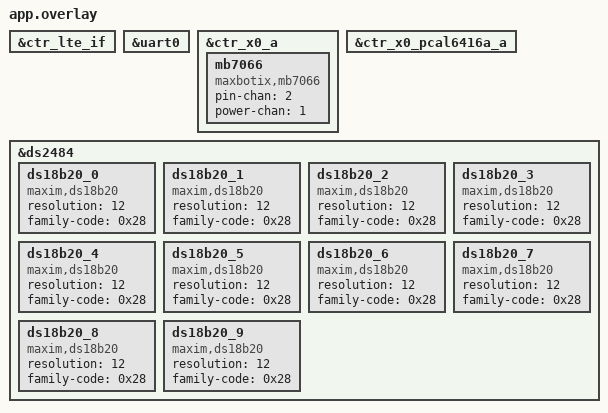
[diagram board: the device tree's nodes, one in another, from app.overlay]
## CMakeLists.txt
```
#
# Copyright (c) 2024 HARDWARIO a.s.
#
#  SPDX-License-Identifier: LicenseRef-HARDWARIO-5-Clause
#

cmake_minimum_required(VERSION 3.20.0)

set(ENV{FW_BUNDLE} "com.hardwario.chester.range")
set(ENV{FW_VERSION} "v1.0.0")
set(ENV{FW_NAME} "CHESTER Range")

find_package(Zephyr REQUIRED HINTS $ENV{ZEPHYR_BASE})

project(chester-range)

target_sources(app PRIVATE src/app_sensor.c)
target_sources(app PRIVATE src/main.c)
target_sources(app PRIVATE src/app_shell.c)
target_sources(app PRIVATE src/app_init.c)
target_sources(app PRIVATE src/app_data.c)
target_sources(app PRIVATE src/app_power.c)
target_sources(app PRIVATE src/app_send.c)
target_sources(app PRIVATE src/app_config.c)
target_sources(app PRIVATE src/app_work.c)
target_sources(app PRIVATE src/app_handler.c)
target_sources(app PRIVATE src/app_backup.c)
target_sources(app PRIVATE src/app_cbor.c)
```

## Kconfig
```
#
# Copyright (c) 2024 HARDWARIO a.s.
#
# SPDX-License-Identifier: LicenseRef-HARDWARIO-5-Clause
#

menu "Application"

# CHESTER RANGE Project | RANGE Variant 

# LTE 
config SHIELD_CTR_LTE
	bool "Enable SHIELD_CTR_LTE"
	default y 

config CTR_LTE
	default y
# MB7066_A 
config SHIELD_CTR_A
	bool "Enable SHIELD_CTR_MB7066_A"
	default y 

config CTR_X0
	default y

config MB7066
	default y
# DS18B20 
config SHIELD_CTR_DS18B20
	bool "Enable SHIELD_CTR_DS18B20"
	default y 

config CTR_DS18B20
	default y
# REPORT_JITTER 
config APP_REPORT_JITTER
	bool "Add random time jitter to report transfers"
	default y 
	select ENTROPY_GENERATOR

endmenu

menu "Zephyr Kernel"
source "Kconfig.zephyr"
endmenu
```

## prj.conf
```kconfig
#
# Copyright (c) 2024 HARDWARIO a.s.
#
#  SPDX-License-Identifier: LicenseRef-HARDWARIO-5-Clause
#

# Configurations
CONFIG_ADC_SHELL=y
CONFIG_CTR_ACCEL=y
CONFIG_CTR_BATT=y
CONFIG_CTR_BUTTON=y
CONFIG_CTR_BUF=y
CONFIG_CTR_DEFAULTS=y
CONFIG_CTR_INFO=y
CONFIG_CTR_LED=y
CONFIG_CTR_LOG=y
CONFIG_CTR_RTC=y
CONFIG_CTR_THERM=y
CONFIG_CTR_WDOG=y
CONFIG_TINYCRYPT=y
CONFIG_TINYCRYPT_SHA256=y
CONFIG_ZCBOR=y
CONFIG_ZCBOR_STOP_ON_ERROR=y
CONFIG_CTR_LTE_CLKSYNC=y
CONFIG_MB7066_TIMER4=y
CONFIG_MB7066_SAMPLE_COUNT=1

# Extra configurations
CONFIG_ADC_TLA2021_INIT_PRIORITY=60

# USER CODE BEGIN Config 
# USER CODE END Config
```

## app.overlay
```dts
/*
 * Copyright (c) 2024 HARDWARIO a.s.
 *
 * SPDX-License-Identifier: LicenseRef-HARDWARIO-5-Clause
 */

/* CHESTER RANGE Project | RANGE Variant */

/* LTE  */
&ctr_lte_if {
	status = "okay";
};

&uart0 {
	status = "okay";
};
/* MB7066_A  */
&ctr_x0_a {
	status = "okay";
	mb7066: mb7066 {
		compatible = "maxbotix,mb7066";
		status = "okay";
		pin-chan = <2>;
		power-chan = <1>;
	};
};

&ctr_x0_pcal6416a_a {
	status = "okay";
};
/* DS18B20  */
&ds2484 {
	ds18b20_0: ds18b20_0 {
		compatible = "maxim,ds18b20";
		resolution = <12>;
		family-code = <0x28>;
	};

	ds18b20_1: ds18b20_1 {
		compatible = "maxim,ds18b20";
		resolution = <12>;
		family-code = <0x28>;
	};

	ds18b20_2: ds18b20_2 {
		compatible = "maxim,ds18b20";
		resolution = <12>;
		family-code = <0x28>;
	};

	ds18b20_3: ds18b20_3 {
		compatible = "maxim,ds18b20";
		resolution = <12>;
		family-code = <0x28>;
	};

	ds18b20_4: ds18b20_4 {
		compatible = "maxim,ds18b20";
		resolution = <12>;
		family-code = <0x28>;
	};

	ds18b20_5: ds18b20_5 {
		compatible = "maxim,ds18b20";
		resolution = <12>;
		family-code = <0x28>;
	};

	ds18b20_6: ds18b20_6 {
		compatible = "maxim,ds18b20";
		resolution = <12>;
		family-code = <0x28>;
	};

	ds18b20_7: ds18b20_7 {
		compatible = "maxim,ds18b20";
		resolution = <12>;
		family-code = <0x28>;
	};

	ds18b20_8: ds18b20_8 {
		compatible = "maxim,ds18b20";
		resolution = <12>;
		family-code = <0x28>;
	};

	ds18b20_9: ds18b20_9 {
		compatible = "maxim,ds18b20";
		resolution = <12>;
		family-code = <0x28>;
	};
};
```

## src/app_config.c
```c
/*
 * Copyright (c) 2024 HARDWARIO a.s.
 *
 * SPDX-License-Identifier: LicenseRef-HARDWARIO-5-Clause
 */

#include "app_config.h"

/* CHESTER includes */
#include <chester/ctr_config.h>

/* Zephyr includes */
#include <zephyr/init.h>
#include <zephyr/kernel.h>
#include <zephyr/logging/log.h>
#include <zephyr/settings/settings.h>
#include <zephyr/shell/shell.h>

/* Standard includes */
#include <ctype.h>
#include <stdbool.h>
#include <stdio.h>
#include <stdlib.h>
#include <string.h>

/* USER CODE BEGIN Includes */
/* USER CODE END Includes */

LOG_MODULE_REGISTER(app_config, LOG_LEVEL_DBG);

#define SETTINGS_PFX "chester-range"

struct app_config g_app_config;

static struct app_config m_app_config_interim = {
	.interval_report = 1800,
	.interval_aggreg = 300,
	.interval_sample = 60,
	.event_report_delay = 1,
	.event_report_rate = 30,
	.backup_report_connected = true,
	.backup_report_disconnected = true,

	/* USER CODE BEGIN Struct Variables */
	/* USER CODE END Struct Variables */
};

/* USER CODE BEGIN Variables */
/* USER CODE END Variables */

static void print_interval_report(const struct shell *shell)
{
	shell_print(shell, "app config interval-report  %d",
			m_app_config_interim.interval_report);
}

int app_config_cmd_config_interval_report(const struct shell *shell, size_t argc, char **argv)
{
	if (argc == 1) {
		print_interval_report(shell);
		return 0;
	}
	if (argc == 2) {
		size_t len = strlen(argv[1]);
		for (size_t i = 0; i < len; i++) {
			if (!isdigit((int)argv[1][i])) {
				shell_error(shell, "invalid format");
				return -EINVAL;
			}
		}
		long value = strtol(argv[1], NULL, 10);
		if (value < 30 || value > 86400) {
			shell_error(shell, "invalid range");
			return -EINVAL;
		}
		m_app_config_interim.interval_report = (int)value;
		return 0;
	}
	shell_help(shell);
	return -EINVAL;
}

static void print_interval_aggreg(const struct shell *shell)
{
	shell_print(shell, "app config interval-aggreg  %d",
			m_app_config_interim.interval_aggreg);
}

int app_config_cmd_config_interval_aggreg(const struct shell *shell, size_t argc, char **argv)
{
	if (argc == 1) {
		print_interval_aggreg(shell);
		return 0;
	}
	if (argc == 2) {
		size_t len = strlen(argv[1]);
		for (size_t i = 0; i < len; i++) {
			if (!isdigit((int)argv[1][i])) {
				shell_error(shell, "invalid format");
				return -EINVAL;
			}
		}
		long value = strtol(argv[1], NULL, 10);
		if (value < 1 || value > 86400) {
			shell_error(shell, "invalid range");
			return -EINVAL;
		}
		m_app_config_interim.interval_aggreg = (int)value;
		return 0;
	}
	shell_help(shell);
	return -EINVAL;
}

static void print_interval_sample(const struct shell *shell)
{
	shell_print(shell, "app config interval-sample  %d",
			m_app_config_interim.interval_sample);
}

int app_config_cmd_config_interval_sample(const struct shell *shell, size_t argc, char **argv)
{
	if (argc == 1) {
		print_interval_sample(shell);
		return 0;
	}
	if (argc == 2) {
		size_t len = strlen(argv[1]);
		for (size_t i = 0; i < len; i++) {
			if (!isdigit((int)argv[1][i])) {
				shell_error(shell, "invalid format");
				return -EINVAL;
			}
		}
		long value = strtol(argv[1], NULL, 10);
		if (value < 1 || value > 86400) {
			shell_error(shell, "invalid range");
			return -EINVAL;
		}
		m_app_config_interim.interval_sample = (int)value;
		return 0;
	}
	shell_help(shell);
	return -EINVAL;
}

static void print_event_report_delay(const struct shell *shell)
{
	shell_print(shell, "app config event-report-delay  %d",
			m_app_config_interim.event_report_delay);
}

int app_config_cmd_config_event_report_delay(const struct shell *shell, size_t argc, char **argv)
{
	if (argc == 1) {
		print_event_report_delay(shell);
		return 0;
	}
	if (argc == 2) {
		size_t len = strlen(argv[1]);
		for (size_t i = 0; i < len; i++) {
			if (!isdigit((int)argv[1][i])) {
				shell_error(shell, "invalid format");
				return -EINVAL;
			}
		}
		long value = strtol(argv[1], NULL, 10);
		if (value < 1 || value > 86400) {
			shell_error(shell, "invalid range");
			return -EINVAL;
		}
		m_app_config_interim.event_report_delay = (int)value;
		return 0;
	}
	shell_help(shell);
	return -EINVAL;
}

static void print_event_report_rate(const struct shell *shell)
{
	shell_print(shell, "app config event-report-rate  %d",
			m_app_config_interim.event_report_rate);
}

int app_config_cmd_config_event_report_rate(const struct shell *shell, size_t argc, char **argv)
{
	if (argc == 1) {
		print_event_report_rate(shell);
		return 0;
	}
	if (argc == 2) {
		size_t len = strlen(argv[1]);
		for (size_t i = 0; i < len; i++) {
			if (!isdigit((int)argv[1][i])) {
				shell_error(shell, "invalid format");
				return -EINVAL;
			}
		}
		long value = strtol(argv[1], NULL, 10);
		if (value < 1 || value > 3600) {
			shell_error(shell, "invalid range");
			return -EINVAL;
		}
		m_app_config_interim.event_report_rate = (int)value;
		return 0;
	}
	shell_help(shell);
	return -EINVAL;
}

static void print_backup_report_connected(const struct shell *shell)
{
	shell_print(shell, "app config backup-report-connected  %s",
			m_app_config_interim.backup_report_connected ? "true" : "false");
}

int app_config_cmd_config_backup_report_connected(const struct shell *shell, size_t argc, char **argv)
{
	if (argc == 1) {
		print_backup_report_connected(shell);                                                    
		return 0;
	}
	if (argc == 2) {
		bool is_false = !strcmp(argv[1], "false");
		bool is_true = !strcmp(argv[1], "true");
		if (is_false) {
			m_app_config_interim.backup_report_connected = false;
		} else if (is_true) {
			m_app_config_interim.backup_report_connected = true;
		} else {
			shell_error(shell, "invalid format");
			return -EINVAL;
		}
		return 0;
	}
	shell_help(shell);
	return -EINVAL;
}

static void print_backup_report_disconnected(const struct shell *shell)
{
	shell_print(shell, "app config backup-report-disconnected  %s",
			m_app_config_interim.backup_report_disconnected ? "true" : "false");
}

int app_config_cmd_config_backup_report_disconnected(const struct shell *shell, size_t argc, char **argv)
{
	if (argc == 1) {
		print_backup_report_disconnected(shell);                                                    
		return 0;
	}
	if (argc == 2) {
		bool is_false = !strcmp(argv[1], "false");
		bool is_true = !strcmp(argv[1], "true");
		if (is_false) {
			m_app_config_interim.backup_report_disconnected = false;
		} else if (is_true) {
			m_app_config_interim.backup_report_disconnected = true;
		} else {
			shell_error(shell, "invalid format");
			return -EINVAL;
		}
		return 0;
	}
	shell_help(shell);
	return -EINVAL;
}

static void print_hygro_t_alarm_hi_report(const struct shell *shell)
{
	shell_print(shell, "app config hygro-t-alarm-hi-report  %s",
			m_app_config_interim.hygro_t_alarm_hi_report ? "true" : "false");
}

int app_config_cmd_config_hygro_t_alarm_hi_report(const struct shell *shell, size_t argc, char **argv)
{
	if (argc == 1) {
		print_hygro_t_alarm_hi_report(shell);                                                    
		return 0;
	}
	if (argc == 2) {
		bool is_false = !strcmp(argv[1], "false");
		bool is_true = !strcmp(argv[1], "true");
		if (is_false) {
			m_app_config_interim.hygro_t_alarm_hi_report = false;
		} else if (is_true) {
			m_app_config_interim.hygro_t_alarm_hi_report = true;
		} else {
			shell_error(shell, "invalid format");
			return -EINVAL;
		}
		return 0;
	}
	shell_help(shell);
	return -EINVAL;
}

static void print_hygro_t_alarm_lo_report(const struct shell *shell)
{
	shell_print(shell, "app config hygro-t-alarm-lo-report  %s",
			m_app_config_interim.hygro_t_alarm_lo_report ? "true" : "false");
}

int app_config_cmd_config_hygro_t_alarm_lo_report(const struct shell *shell, size_t argc, char **argv)
{
	if (argc == 1) {
		print_hygro_t_alarm_lo_report(shell);                                                    
		return 0;
	}
	if (argc == 2) {
		bool is_false = !strcmp(argv[1], "false");
		bool is_true = !strcmp(argv[1], "true");
		if (is_false) {
			m_app_config_interim.hygro_t_alarm_lo_report = false;
		} else if (is_true) {
			m_app_config_interim.hygro_t_alarm_lo_report = true;
		} else {
			shell_error(shell, "invalid format");
			return -EINVAL;
		}
		return 0;
	}
	shell_help(shell);
	return -EINVAL;
}

static void print_hygro_t_alarm_hi_thr(const struct shell *shell)
{
	shell_print(shell, "app config hygro-t-alarm-hi-thr %.1f",
			m_app_config_interim.hygro_t_alarm_hi_thr);
}

int app_config_cmd_config_hygro_t_alarm_hi_thr(const struct shell *shell, size_t argc, char **argv)
{
	if (argc == 1) {
		print_hygro_t_alarm_hi_thr(shell);
		return 0;
	}
	if (argc == 2) {
		float value;
		int ret = sscanf(argv[1], "%f", &value);
		if (ret != 1) {
			shell_error(shell, "invalid value");
			return -EINVAL;
		}
		if (value < -40.0 || value > 125.0) 
		{
			shell_error(shell, "invalid range");
			return -EINVAL;
		}
		m_app_config_interim.hygro_t_alarm_hi_thr = value;
		return 0;
	}
	shell_help(shell);
	return -EINVAL;
}

static void print_hygro_t_alarm_hi_hst(const struct shell *shell)
{
	shell_print(shell, "app config hygro-t-alarm-hi-hst %.1f",
			m_app_config_interim.hygro_t_alarm_hi_hst);
}

int app_config_cmd_config_hygro_t_alarm_hi_hst(const struct shell *shell, size_t argc, char **argv)
{
	if (argc == 1) {
		print_hygro_t_alarm_hi_hst(shell);
		return 0;
	}
	if (argc == 2) {
		float value;
		int ret = sscanf(argv[1], "%f", &value);
		if (ret != 1) {
			shell_error(shell, "invalid value");
			return -EINVAL;
		}
		if (value < 0.0 || value > 100.0) 
		{
			shell_error(shell, "invalid range");
			return -EINVAL;
		}
		m_app_config_interim.hygro_t_alarm_hi_hst = value;
		return 0;
	}
	shell_help(shell);
	return -EINVAL;
}

static void print_hygro_t_alarm_lo_thr(const struct shell *shell)
{
	shell_print(shell, "app config hygro-t-alarm-lo-thr %.1f",
			m_app_config_interim.hygro_t_alarm_lo_thr);
}

int app_config_cmd_config_hygro_t_alarm_lo_thr(const struct shell *shell, size_t argc, char **argv)
{
	if (argc == 1) {
		print_hygro_t_alarm_lo_thr(shell);
		return 0;
	}
	if (argc == 2) {
		float value;
		int ret = sscanf(argv[1], "%f", &value);
		if (ret != 1) {
			shell_error(shell, "invalid value");
			return -EINVAL;
		}
		if (value < -40.0 || value > 125.0) 
		{
			shell_error(shell, "invalid range");
			return -EINVAL;
		}
		m_app_config_interim.hygro_t_alarm_lo_thr = value;
		return 0;
	}
	shell_help(shell);
	return -EINVAL;
}

static void print_hygro_t_alarm_lo_hst(const struct shell *shell)
{
	shell_print(shell, "app config hygro-t-alarm-lo-hst %.1f",
			m_app_config_interim.hygro_t_alarm_lo_hst);
}

int app_config_cmd_config_hygro_t_alarm_lo_hst(const struct shell *shell, size_t argc, char **argv)
{
	if (argc == 1) {
		print_hygro_t_alarm_lo_hst(shell);
		return 0;
	}
	if (argc == 2) {
		float value;
		int ret = sscanf(argv[1], "%f", &value);
		if (ret != 1) {
			shell_error(shell, "invalid value");
			return -EINVAL;
		}
		if (value < 0.0 || value > 100.0) 
		{
			shell_error(shell, "invalid range");
			return -EINVAL;
		}
		m_app_config_interim.hygro_t_alarm_lo_hst = value;
		return 0;
	}
	shell_help(shell);
	return -EINVAL;
}

int app_config_cmd_config_show(const struct shell *shell, size_t argc, char **argv)
{
	print_interval_report(shell);
	print_interval_aggreg(shell);
	print_interval_sample(shell);
	print_event_report_delay(shell);
	print_event_report_rate(shell);
	print_backup_report_connected(shell);
	print_backup_report_disconnected(shell);
	print_hygro_t_alarm_hi_report(shell);
	print_hygro_t_alarm_lo_report(shell);
	print_hygro_t_alarm_hi_thr(shell);
	print_hygro_t_alarm_hi_hst(shell);
	print_hygro_t_alarm_lo_thr(shell);
	print_hygro_t_alarm_lo_hst(shell);
	
	return 0;
}

/* USER CODE BEGIN Functions 1 */
/* USER CODE END Functions 1 */

static int h_commit(void)
{
	LOG_DBG("Loaded settings in full");
	memcpy(&g_app_config, &m_app_config_interim, sizeof(g_app_config));

	return 0;
}

static int h_set(const char *key, size_t len, settings_read_cb read_cb, void *cb_arg) 
{
	int ret;
	const char *next;
	if (settings_name_steq(key, "interval-report", &next) && !next) {
		if (len != sizeof(m_app_config_interim.interval_report)) {
			return -EINVAL;
		}
		ret = read_cb(cb_arg, &m_app_config_interim.interval_report, len);
		if (ret < 0) {
			LOG_ERR("Call `read_cb` failed: %d", ret);
			return ret;
		}
		return 0;
	}

	if (settings_name_steq(key, "interval-aggreg", &next) && !next) {
		if (len != sizeof(m_app_config_interim.interval_aggreg)) {
			return -EINVAL;
		}
		ret = read_cb(cb_arg, &m_app_config_interim.interval_aggreg, len);
		if (ret < 0) {
			LOG_ERR("Call `read_cb` failed: %d", ret);
			return ret;
		}
		return 0;
	}

	if (settings_name_steq(key, "interval-sample", &next) && !next) {
		if (len != sizeof(m_app_config_interim.interval_sample)) {
			return -EINVAL;
		}
		ret = read_cb(cb_arg, &m_app_config_interim.interval_sample, len);
		if (ret < 0) {
			LOG_ERR("Call `read_cb` failed: %d", ret);
			return ret;
		}
		return 0;
	}

	if (settings_name_steq(key, "event-report-delay", &next) && !next) {
		if (len != sizeof(m_app_config_interim.event_report_delay)) {
			return -EINVAL;
		}
		ret = read_cb(cb_arg, &m_app_config_interim.event_report_delay, len);
		if (ret < 0) {
			LOG_ERR("Call `read_cb` failed: %d", ret);
			return ret;
		}
		return 0;
	}

	if (settings_name_steq(key, "event-report-rate", &next) && !next) {
		if (len != sizeof(m_app_config_interim.event_report_rate)) {
			return -EINVAL;
		}
		ret = read_cb(cb_arg, &m_app_config_interim.event_report_rate, len);
		if (ret < 0) {
			LOG_ERR("Call `read_cb` failed: %d", ret);
			return ret;
		}
		return 0;
	}

	if (settings_name_steq(key, "backup-report-connected", &next) && !next) {
		if (len != sizeof(m_app_config_interim.backup_report_connected)) {
			return -EINVAL;
		}
		ret = read_cb(cb_arg, &m_app_config_interim.backup_report_connected, len);
		if (ret < 0) {
			LOG_ERR("Call `read_cb` failed: %d", ret);
			return ret;
		}
		return 0;
	}

	if (settings_name_steq(key, "backup-report-disconnected", &next) && !next) {
		if (len != sizeof(m_app_config_interim.backup_report_disconnected)) {
			return -EINVAL;
		}
		ret = read_cb(cb_arg, &m_app_config_interim.backup_report_disconnected, len);
		if (ret < 0) {
			LOG_ERR("Call `read_cb` failed: %d", ret);
			return ret;
		}
		return 0;
	}

	if (settings_name_steq(key, "hygro-t-alarm-hi-report", &next) && !next) {
		if (len != sizeof(m_app_config_interim.hygro_t_alarm_hi_report)) {
			return -EINVAL;
		}
		ret = read_cb(cb_arg, &m_app_config_interim.hygro_t_alarm_hi_report, len);
		if (ret < 0) {
			LOG_ERR("Call `read_cb` failed: %d", ret);
			return ret;
		}
		return 0;
	}

	if (settings_name_steq(key, "hygro-t-alarm-lo-report", &next) && !next) {
		if (len != sizeof(m_app_config_interim.hygro_t_alarm_lo_report)) {
			return -EINVAL;
		}
		ret = read_cb(cb_arg, &m_app_config_interim.hygro_t_alarm_lo_report, len);
		if (ret < 0) {
			LOG_ERR("Call `read_cb` failed: %d", ret);
			return ret;
		}
		return 0;
	}

	if (settings_name_steq(key, "hygro-t-alarm-hi-thr", &next) && !next) {
		if (len != sizeof(m_app_config_interim.hygro_t_alarm_hi_thr)) {
			return -EINVAL;
		}
		ret = read_cb(cb_arg, &m_app_config_interim.hygro_t_alarm_hi_thr, len);
		if (ret < 0) {
			LOG_ERR("Call `read_cb` failed: %d", ret);
			return ret;
		}
		return 0;
	}

	if (settings_name_steq(key, "hygro-t-alarm-hi-hst", &next) && !next) {
		if (len != sizeof(m_app_config_interim.hygro_t_alarm_hi_hst)) {
			return -EINVAL;
		}
		ret = read_cb(cb_arg, &m_app_config_interim.hygro_t_alarm_hi_hst, len);
		if (ret < 0) {
			LOG_ERR("Call `read_cb` failed: %d", ret);
			return ret;
		}
		return 0;
	}

	if (settings_name_steq(key, "hygro-t-alarm-lo-thr", &next) && !next) {
		if (len != sizeof(m_app_config_interim.hygro_t_alarm_lo_thr)) {
			return -EINVAL;
		}
		ret = read_cb(cb_arg, &m_app_config_interim.hygro_t_alarm_lo_thr, len);
		if (ret < 0) {
			LOG_ERR("Call `read_cb` failed: %d", ret);
			return ret;
		}
		return 0;
	}

	if (settings_name_steq(key, "hygro-t-alarm-lo-hst", &next) && !next) {
		if (len != sizeof(m_app_config_interim.hygro_t_alarm_lo_hst)) {
			return -EINVAL;
		}
		ret = read_cb(cb_arg, &m_app_config_interim.hygro_t_alarm_lo_hst, len);
		if (ret < 0) {
			LOG_ERR("Call `read_cb` failed: %d", ret);
			return ret;
		}
		return 0;
	}

	/* USER CODE BEGIN Functions 2 */
	/* USER CODE END Functions 2 */

	return 0;
}

static int h_export(int (*export_func)(const char *name, const void *val, size_t val_len))
{
	int ret;

	ret = export_func("chester-range/interval-report", &m_app_config_interim.interval_report,
					  sizeof( m_app_config_interim.interval_report));
	if (ret < 0) {
		return ret;
	}

	ret = export_func("chester-range/interval-aggreg", &m_app_config_interim.interval_aggreg,
					  sizeof( m_app_config_interim.interval_aggreg));
	if (ret < 0) {
		return ret;
	}

	ret = export_func("chester-range/interval-sample", &m_app_config_interim.interval_sample,
					  sizeof( m_app_config_interim.interval_sample));
	if (ret < 0) {
		return ret;
	}

	ret = export_func("chester-range/event-report-delay", &m_app_config_interim.event_report_delay,
					  sizeof( m_app_config_interim.event_report_delay));
	if (ret < 0) {
		return ret;
	}

	ret = export_func("chester-range/event-report-rate", &m_app_config_interim.event_report_rate,
					  sizeof( m_app_config_interim.event_report_rate));
	if (ret < 0) {
		return ret;
	}

	ret = export_func("chester-range/backup-report-connected", &m_app_config_interim.backup_report_connected,
					  sizeof( m_app_config_interim.backup_report_connected));
	if (ret < 0) {
		return ret;
	}

	ret = export_func("chester-range/backup-report-disconnected", &m_app_config_interim.backup_report_disconnected,
					  sizeof( m_app_config_interim.backup_report_disconnected));
	if (ret < 0) {
		return ret;
	}

	ret = export_func("chester-range/hygro-t-alarm-hi-report", &m_app_config_interim.hygro_t_alarm_hi_report,
					  sizeof( m_app_config_interim.hygro_t_alarm_hi_report));
	if (ret < 0) {
		return ret;
	}

	ret = export_func("chester-range/hygro-t-alarm-lo-report", &m_app_config_interim.hygro_t_alarm_lo_report,
					  sizeof( m_app_config_interim.hygro_t_alarm_lo_report));
	if (ret < 0) {
		return ret;
	}

	ret = export_func("chester-range/hygro-t-alarm-hi-thr", &m_app_config_interim.hygro_t_alarm_hi_thr,
					  sizeof( m_app_config_interim.hygro_t_alarm_hi_thr));
	if (ret < 0) {
		return ret;
	}

	ret = export_func("chester-range/hygro-t-alarm-hi-hst", &m_app_config_interim.hygro_t_alarm_hi_hst,
					  sizeof( m_app_config_interim.hygro_t_alarm_hi_hst));
	if (ret < 0) {
		return ret;
	}

	ret = export_func("chester-range/hygro-t-alarm-lo-thr", &m_app_config_interim.hygro_t_alarm_lo_thr,
					  sizeof( m_app_config_interim.hygro_t_alarm_lo_thr));
	if (ret < 0) {
		return ret;
	}

	ret = export_func("chester-range/hygro-t-alarm-lo-hst", &m_app_config_interim.hygro_t_alarm_lo_hst,
					  sizeof( m_app_config_interim.hygro_t_alarm_lo_hst));
	if (ret < 0) {
		return ret;
	}

	/* USER CODE BEGIN Functions 3 */
	/* USER CODE END Functions 3 */

	return 0;
}

static int init(void) 
{
	int ret;

	LOG_INF("System initialization");

	static struct settings_handler sh = {
		.name = SETTINGS_PFX,
		.h_set = h_set,
		.h_commit = h_commit,
		.h_export = h_export,
	};

	ret = settings_register(&sh);

	if (ret < 0) {
		LOG_ERR("Call `settings_register` failed: %d", ret);
		return ret;
	}

	ret = settings_load_subtree(SETTINGS_PFX);

	if (ret < 0) {
		LOG_ERR("Call `settings_load_subtree` failed: %d", ret);
		return ret;
	}

	ctr_config_append_show(SETTINGS_PFX, app_config_cmd_config_show);

	/* USER CODE BEGIN Functions 4 */
	/* USER CODE END Functions 4 */

	return 0;
}

SYS_INIT(init, APPLICATION, CONFIG_APPLICATION_INIT_PRIORITY);
```

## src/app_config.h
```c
/*
 * Copyright (c) 2024 HARDWARIO a.s.
 *
 * SPDX-License-Identifier: LicenseRef-HARDWARIO-5-Clause
 */

#ifndef APP_CONFIG_H_
#define APP_CONFIG_H_

/* Zephyr includes */
#include <zephyr/shell/shell.h>

/* Standard includes */
#include <stdbool.h>
#include <stddef.h>

/* USER CODE BEGIN Includes */
/* USER CODE END Includes */

#ifdef __cplusplus
extern "C" {
#endif

struct app_config {
	int interval_report;
	int interval_aggreg;
	int interval_sample;
	int event_report_delay;
	int event_report_rate;
	bool backup_report_connected;
	bool backup_report_disconnected;
	bool hygro_t_alarm_hi_report;
	bool hygro_t_alarm_lo_report;
	float hygro_t_alarm_hi_thr;
	float hygro_t_alarm_hi_hst;
	float hygro_t_alarm_lo_thr;
	float hygro_t_alarm_lo_hst;

	/* USER CODE BEGIN Struct Variables */
	/* USER CODE END Struct Variables */
};

extern struct app_config g_app_config;

/* USER CODE BEGIN Variables */
/* USER CODE END Variables */

int app_config_cmd_config_show(const struct shell *shell, size_t argc, char **argv);
int app_config_cmd_config_interval_report(const struct shell *shell, size_t argc, char **argv);
int app_config_cmd_config_interval_aggreg(const struct shell *shell, size_t argc, char **argv);
int app_config_cmd_config_interval_sample(const struct shell *shell, size_t argc, char **argv);
int app_config_cmd_config_event_report_delay(const struct shell *shell, size_t argc, char **argv);
int app_config_cmd_config_event_report_rate(const struct shell *shell, size_t argc, char **argv);
int app_config_cmd_config_backup_report_connected(const struct shell *shell, size_t argc, char **argv);
int app_config_cmd_config_backup_report_disconnected(const struct shell *shell, size_t argc, char **argv);
int app_config_cmd_config_hygro_t_alarm_hi_report(const struct shell *shell, size_t argc, char **argv);
int app_config_cmd_config_hygro_t_alarm_lo_report(const struct shell *shell, size_t argc, char **argv);
int app_config_cmd_config_hygro_t_alarm_hi_thr(const struct shell *shell, size_t argc, char **argv);
int app_config_cmd_config_hygro_t_alarm_hi_hst(const struct shell *shell, size_t argc, char **argv);
int app_config_cmd_config_hygro_t_alarm_lo_thr(const struct shell *shell, size_t argc, char **argv);
int app_config_cmd_config_hygro_t_alarm_lo_hst(const struct shell *shell, size_t argc, char **argv);

/* USER CODE BEGIN Functions 1 */
/* USER CODE END Functions 1 */

#ifdef __cplusplus
}
#endif

#endif /* APP_CONFIG_H_ */
```

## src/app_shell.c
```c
/*
 * Copyright (c) 2024 HARDWARIO a.s.
 *
 * SPDX-License-Identifier: LicenseRef-HARDWARIO-5-Clause
 */

#include "app_config.h"
#include "app_work.h"

/* Zephyr includes */
#include <zephyr/kernel.h>
#include <zephyr/logging/log.h>
#include <zephyr/shell/shell.h>

/* Standard includes */
#include <errno.h>
#include <stdlib.h>

/* USER CODE BEGIN Includes */
/* USER CODE END Includes */

LOG_MODULE_REGISTER(app_shell, LOG_LEVEL_INF);

static int cmd_sample(const struct shell *shell, size_t argc, char **argv)
{
	if (argc > 1) {
		shell_error(shell, "unknown parameter: %s", argv[1]);
		shell_help(shell);
		return -EINVAL;
	}

	app_work_sample();

	return 0;
}

static int cmd_aggreg(const struct shell *shell, size_t argc, char **argv)
{
	if (argc > 1) {
		shell_error(shell, "unknown parameter: %s", argv[1]);
		shell_help(shell);
		return -EINVAL;
	}

	app_work_aggreg();

	return 0;
}

static int cmd_send(const struct shell *shell, size_t argc, char **argv)
{
	if (argc > 1) {
		shell_error(shell, "unknown parameter: %s", argv[1]);
		shell_help(shell);
		return -EINVAL;
	}

	app_work_send();

	return 0;
}

static int print_help(const struct shell *shell, size_t argc, char **argv)
{
	if (argc > 1) {
		shell_error(shell, "command not found: %s", argv[1]);
		shell_help(shell);
		return -EINVAL;
	}

	shell_help(shell);
	return 0;
}

/* clang-format off */

SHELL_STATIC_SUBCMD_SET_CREATE(
	sub_app_config,
   
	SHELL_CMD_ARG(show, NULL,
				  "List current configuration.",
				  app_config_cmd_config_show, 1, 0),
	
	SHELL_CMD_ARG(interval-report, NULL,
				  "Get/Set report interval in seconds (format: <30-86400>).",
				  app_config_cmd_config_interval_report, 1, 1),
	
	SHELL_CMD_ARG(interval-aggreg, NULL,
				  "Get/Set aggregate interval in seconds (format: <1-86400>).",
				  app_config_cmd_config_interval_aggreg, 1, 1),
	
	SHELL_CMD_ARG(interval-sample, NULL,
				  "Get/Set sample interval in seconds (format: <1-86400>).",
				  app_config_cmd_config_interval_sample, 1, 1),
	
	SHELL_CMD_ARG(event-report-delay, NULL,
				  "Get/Set event report delay in seconds (format: <1-86400>).",
				  app_config_cmd_config_event_report_delay, 1, 1),
	
	SHELL_CMD_ARG(event-report-rate, NULL,
				  "Get/Set event report rate in reports per hour (format: <1-3600>).",
				  app_config_cmd_config_event_report_rate, 1, 1),
	
	SHELL_CMD_ARG(backup-report-connected, NULL,
				  "Get/Set report when backup is active (format: true, false).",
				  app_config_cmd_config_backup_report_connected, 1, 1),
	
	SHELL_CMD_ARG(backup-report-disconnected, NULL,
				  "Get/Set report when backup is inactive (format: true, false).",
				  app_config_cmd_config_backup_report_disconnected, 1, 1),
	
	SHELL_CMD_ARG(hygro-t-alarm-hi-report, NULL,
				  "Get/Set report when hygro high temperature alarm is crossed (format: true, false).",
				  app_config_cmd_config_hygro_t_alarm_hi_report, 1, 1),
	
	SHELL_CMD_ARG(hygro-t-alarm-lo-report, NULL,
				  "Get/Set report when hygro low temperature alarm is crossed (format: true, false).",
				  app_config_cmd_config_hygro_t_alarm_lo_report, 1, 1),
	
	SHELL_CMD_ARG(hygro-t-alarm-hi-thr, NULL,
				  "Get/Set hygro high temperature alarm threshold (format: <-40.0..125.0>).",
				  app_config_cmd_config_hygro_t_alarm_hi_thr, 1, 1),
	
	SHELL_CMD_ARG(hygro-t-alarm-hi-hst, NULL,
				  "Get/Set hygro high temperature alarm hysteresis (format: <0.0..100.0>).",
				  app_config_cmd_config_hygro_t_alarm_hi_hst, 1, 1),
	
	SHELL_CMD_ARG(hygro-t-alarm-lo-thr, NULL,
				  "Get/Set hygro low temperature alarm threshold (format: <-40.0..125.0>).",
				  app_config_cmd_config_hygro_t_alarm_lo_thr, 1, 1),
	
	SHELL_CMD_ARG(hygro-t-alarm-lo-hst, NULL,
				  "Get/Set hygro low temperature alarm hysteresis (format: <0.0..100.0>).",
				  app_config_cmd_config_hygro_t_alarm_lo_hst, 1, 1),
	
	/* USER CODE BEGIN Functions 1 */
	/* USER CODE END Functions 1 */

	SHELL_SUBCMD_SET_END
);

SHELL_STATIC_SUBCMD_SET_CREATE(
	sub_app,

	SHELL_CMD_ARG(config, &sub_app_config, "Configuration commands.",
				  print_help, 1, 0),
		
	SHELL_SUBCMD_SET_END

	/* USER CODE BEGIN Functions 2 */
	/* USER CODE END Functions 2 */
);

SHELL_CMD_REGISTER(app, &sub_app, "Application commands.", print_help);

SHELL_CMD_REGISTER(sample, NULL,"Sample immediately.", cmd_sample);
SHELL_CMD_REGISTER(aggreg, NULL,"Aggregate data immediately", cmd_aggreg);
SHELL_CMD_REGISTER(send, NULL,"Send data immediately.", cmd_send);

/* USER CODE BEGIN Functions 3 */
/* USER CODE END Functions 3 */

/* clang-format on */
```
